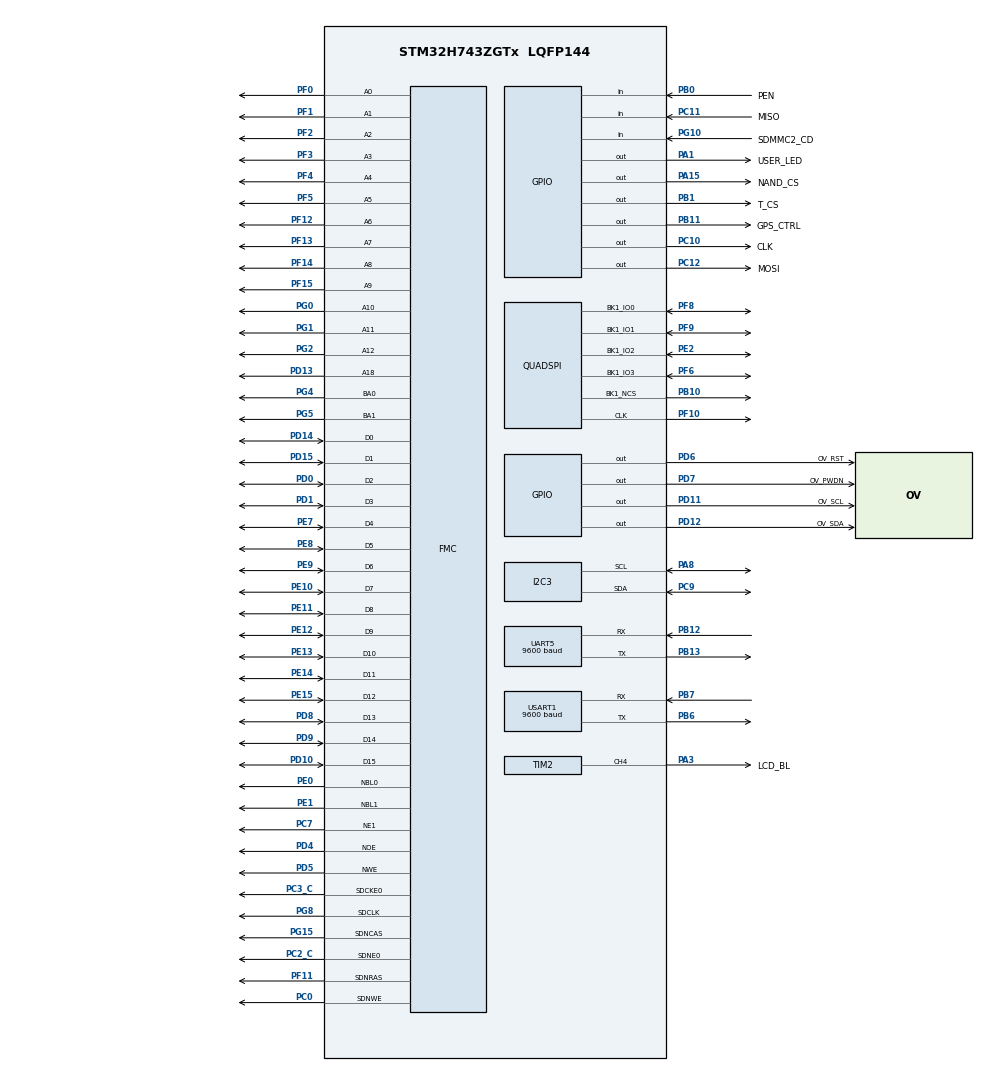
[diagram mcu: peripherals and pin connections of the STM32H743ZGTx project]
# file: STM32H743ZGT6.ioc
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CORTEX_M7.AccessPermission_S-Cortex_Memory_Protection_Unit_Region1_Settings_S=MPU_REGION_FULL_ACCESS
CORTEX_M7.AccessPermission_S-Cortex_Memory_Protection_Unit_Region2_Settings_S=MPU_REGION_FULL_ACCESS
CORTEX_M7.AccessPermission_Spec=MPU_REGION_FULL_ACCESS
CORTEX_M7.BaseAddress_S-Cortex_Memory_Protection_Unit_Region1_Settings_S=0xC0000000
CORTEX_M7.BaseAddress_S-Cortex_Memory_Protection_Unit_Region2_Settings_S=0x24000000
CORTEX_M7.BaseAddress_Spec=0x60000000
CORTEX_M7.CPU_DCache=Enabled
CORTEX_M7.CPU_ICache=Enabled
CORTEX_M7.DisableExec_Spec=MPU_INSTRUCTION_ACCESS_ENABLE
CORTEX_M7.Enable_S-Cortex_Memory_Protection_Unit_Region1_Settings_S=MPU_REGION_ENABLE
CORTEX_M7.Enable_S-Cortex_Memory_Protection_Unit_Region2_Settings_S=MPU_REGION_ENABLE
CORTEX_M7.IsBufferable_S-Cortex_Memory_Protection_Unit_Region1_Settings_S=MPU_ACCESS_BUFFERABLE
CORTEX_M7.IsBufferable_S-Cortex_Memory_Protection_Unit_Region2_Settings_S=MPU_ACCESS_BUFFERABLE
CORTEX_M7.IsBufferable_Spec=MPU_ACCESS_BUFFERABLE
CORTEX_M7.IsCacheable_S-Cortex_Memory_Protection_Unit_Region1_Settings_S=MPU_ACCESS_CACHEABLE
CORTEX_M7.IsCacheable_S-Cortex_Memory_Protection_Unit_Region2_Settings_S=MPU_ACCESS_CACHEABLE
CORTEX_M7.IsCacheable_Spec=MPU_ACCESS_NOT_CACHEABLE
CORTEX_M7.IsShareable_Spec=MPU_ACCESS_NOT_SHAREABLE
CORTEX_M7.Size_S-Cortex_Memory_Protection_Unit_Region1_Settings_S=MPU_REGION_SIZE_32MB
CORTEX_M7.Size_S-Cortex_Memory_Protection_Unit_Region2_Settings_S=MPU_REGION_SIZE_512KB
CORTEX_M7.Size_Spec=MPU_REGION_SIZE_256MB
CORTEX_M7.SubRegionDisable_Spec=0x0
CORTEX_M7.default_mode_Activation=1
Dma.MEMTOMEM.0.Direction=DMA_MEMORY_TO_MEMORY
Dma.MEMTOMEM.0.EventEnable=DISABLE
Dma.MEMTOMEM.0.FIFOMode=DMA_FIFOMODE_ENABLE
Dma.MEMTOMEM.0.FIFOThreshold=DMA_FIFO_THRESHOLD_FULL
Dma.MEMTOMEM.0.Instance=DMA2_Stream0
Dma.MEMTOMEM.0.MemBurst=DMA_MBURST_SINGLE
Dma.MEMTOMEM.0.MemDataAlignment=DMA_MDATAALIGN_HALFWORD
Dma.MEMTOMEM.0.MemInc=DMA_MINC_ENABLE
Dma.MEMTOMEM.0.Mode=DMA_NORMAL
Dma.MEMTOMEM.0.PeriphBurst=DMA_PBURST_SINGLE
Dma.MEMTOMEM.0.PeriphDataAlignment=DMA_PDATAALIGN_HALFWORD
Dma.MEMTOMEM.0.PeriphInc=DMA_PINC_ENABLE
Dma.MEMTOMEM.0.Polarity=HAL_DMAMUX_REQ_GEN_RISING
Dma.MEMTOMEM.0.Priority=DMA_PRIORITY_HIGH
Dma.MEMTOMEM.0.RequestNumber=1
Dma.MEMTOMEM.0.SignalID=NONE
Dma.MEMTOMEM.0.SyncEnable=DISABLE
Dma.MEMTOMEM.0.SyncPolarity=HAL_DMAMUX_SYNC_NO_EVENT
Dma.MEMTOMEM.0.SyncRequestNumber=1
Dma.MEMTOMEM.0.SyncSignalID=NONE
Dma.Request0=MEMTOMEM
FATFS._CODE_PAGE=936
FATFS._MAX_SS=4096
FATFS._USE_FIND=1
FATFS._USE_LFN=2
FMC.BusTurnAroundDuration1=0
FMC.CASLatency1=FMC_SDRAM_CAS_LATENCY_3
FMC.ColumnBitsNumber1=FMC_SDRAM_COLUMN_BITS_NUM_9
FMC.DataSetupTime1=60
FMC.ExitSelfRefreshDelay1=8
FMC.ExtendedAddressSetupTime1=9
FMC.ExtendedBusTurnAroundDuration1=0
FMC.ExtendedDataSetupTime1=8
FMC.ExtendedMode1=FMC_EXTENDED_MODE_ENABLE
FMC.LoadToActiveDelay1=2
FMC.RCDDelay1=4
FMC.RPDelay1=2
FMC.RPDelay2=2
FMC.ReadBurst1=FMC_SDRAM_RBURST_ENABLE
FMC.ReadBurst2=FMC_SDRAM_RBURST_ENABLE
FMC.RowCycleDelay1=6
FMC.RowCycleDelay2=6
FMC.SDClockPeriod1=FMC_SDRAM_CLOCK_PERIOD_2
FMC.SDClockPeriod2=FMC_SDRAM_CLOCK_PERIOD_2
FMC.SelfRefreshTime1=6
FMC.WriteFifo1=FMC_WRITE_FIFO_ENABLE
FMC.WriteRecoveryTime1=2
I2C3.Timing=0x307075B1
Mcu.Family=STM32H7
Mcu.Name=STM32H743ZGTx
Mcu.Package=LQFP144
Mdma.MDMA_Channel0.QUADSPI_FIFO_TH.0.BlockCount=0
Mdma.MDMA_Channel0.QUADSPI_FIFO_TH.0.BlockDataLength=0
Mdma.MDMA_Channel0.QUADSPI_FIFO_TH.0.BufferTransferLength=128
Mdma.MDMA_Channel0.QUADSPI_FIFO_TH.0.CircularMode=MDMA_LINEAR_LIST
Mdma.MDMA_Channel0.QUADSPI_FIFO_TH.0.DataAlignment=MDMA_DATAALIGN_PACKENABLE
Mdma.MDMA_Channel0.QUADSPI_FIFO_TH.0.DestBlockAddressOffset=0
Mdma.MDMA_Channel0.QUADSPI_FIFO_TH.0.DestBurst=MDMA_DEST_BURST_SINGLE
Mdma.MDMA_Channel0.QUADSPI_FIFO_TH.0.DestDataSize=MDMA_DEST_DATASIZE_BYTE
Mdma.MDMA_Channel0.QUADSPI_FIFO_TH.0.DestinationInc=MDMA_DEST_INC_DISABLE
Mdma.MDMA_Channel0.QUADSPI_FIFO_TH.0.DstAddress=0
Mdma.MDMA_Channel0.QUADSPI_FIFO_TH.0.Endianness=MDMA_LITTLE_ENDIANNESS_PRESERVE
Mdma.MDMA_Channel0.QUADSPI_FIFO_TH.0.Instance=MDMA_Channel0
Mdma.MDMA_Channel0.QUADSPI_FIFO_TH.0.MaskAddress=0
Mdma.MDMA_Channel0.QUADSPI_FIFO_TH.0.MaskData=0
Mdma.MDMA_Channel0.QUADSPI_FIFO_TH.0.Priority=MDMA_PRIORITY_MEDIUM
Mdma.MDMA_Channel0.QUADSPI_FIFO_TH.0.Rank=First
Mdma.MDMA_Channel0.QUADSPI_FIFO_TH.0.SourceBlockAddressOffset=0
Mdma.MDMA_Channel0.QUADSPI_FIFO_TH.0.SourceBurst=MDMA_SOURCE_BURST_SINGLE
Mdma.MDMA_Channel0.QUADSPI_FIFO_TH.0.SourceDataSize=MDMA_SRC_DATASIZE_BYTE
Mdma.MDMA_Channel0.QUADSPI_FIFO_TH.0.SourceInc=MDMA_SRC_INC_BYTE
Mdma.MDMA_Channel0.QUADSPI_FIFO_TH.0.SrcAddress=0
Mdma.MDMA_Channel0.QUADSPI_FIFO_TH.0.TransferTriggerMode=MDMA_BUFFER_TRANSFER
Mdma.MDMA_Channel0.Request0=QUADSPI_FIFO_TH
Mdma.MDMA_Channel0.RequestsNb=1
Mdma.RequestSet0=MDMA_Channel0
Mdma.RequestSetsNb=1
NVIC.DMA2_Stream0_IRQn=true\:0\:0\:false\:false\:true\:true\:true\:true
NVIC.MDMA_IRQn=true\:0\:0\:false\:false\:true\:false\:true\:true
NVIC.PriorityGroup=NVIC_PRIORITYGROUP_4
NVIC.QUADSPI_IRQn=true\:0\:0\:true\:false\:true\:true\:true\:true
NVIC.TIM3_IRQn=true\:1\:0\:true\:false\:true\:true\:true\:true
NVIC.UART5_IRQn=true\:2\:0\:true\:false\:true\:true\:true\:true
NVIC.USART1_IRQn=true\:2\:0\:true\:false\:true\:true\:true\:true
PA1.GPIO_Label=USER_LED
PA1.Signal=GPIO_Output
PA11.Signal=USB_OTG_FS_DM
PA12.Signal=USB_OTG_FS_DP
PA13\ (JTMS/SWDIO).Mode=Serial_Wire
PA13\ (JTMS/SWDIO).Signal=DEBUG_JTMS-SWDIO
PA14\ (JTCK/SWCLK).Mode=Serial_Wire
PA14\ (JTCK/SWCLK).Signal=DEBUG_JTCK-SWCLK
PA15\ (JTDI).GPIO_Label=NAND_CS
PA15\ (JTDI).Signal=GPIO_Output
PA3.GPIO_Label=LCD_BL
PA3.Signal=S_TIM2_CH4
PA8.Mode=I2C
PA8.Signal=I2C3_SCL
PB0.GPIO_Label=PEN
PB0.GPIO_PuPd=GPIO_PULLUP
PB0.Signal=GPIO_Input
PB1.GPIO_Label=T_CS
PB1.Signal=GPIO_Output
PB10.GPIO_PuPd=GPIO_NOPULL
PB10.GPIO_Speed=GPIO_SPEED_FREQ_VERY_HIGH
PB10.Mode=Single Bank 1
PB10.Signal=QUADSPI_BK1_NCS
PB11.GPIO_Label=GPS_CTRL
PB11.GPIO_PuPd=GPIO_PULLUP
PB11.GPIO_Speed=GPIO_SPEED_FREQ_MEDIUM
PB11.PinState=GPIO_PIN_RESET
PB11.Signal=GPIO_Output
PB12.Mode=Asynchronous
PB12.Signal=UART5_RX
PB13.Mode=Asynchronous
PB13.Signal=UART5_TX
PB6.Mode=Asynchronous
PB6.Signal=USART1_TX
PB7.Mode=Asynchronous
PB7.Signal=USART1_RX
PC0.Signal=FMC_SDNWE
PC10.GPIO_Label=CLK
PC10.Signal=GPIO_Output
PC11.GPIO_Label=MISO
PC11.GPIO_PuPd=GPIO_PULLUP
PC11.Signal=GPIO_Input
PC12.GPIO_Label=MOSI
PC12.Signal=GPIO_Output
PC14-OSC32_IN\ (OSC32_IN).Signal=RCC_OSC32_IN
PC15-OSC32_OUT\ (OSC32_OUT).Signal=RCC_OSC32_OUT
PC2_C.Mode=SdramChipSelect1_1
PC2_C.Signal=FMC_SDNE0
PC3_C.Mode=SdramChipSelect1_1
PC3_C.Signal=FMC_SDCKE0
PC7.Mode=NorPsramChipSelect1_1
PC7.Signal=FMC_NE1
PC9.Mode=I2C
PC9.Signal=I2C3_SDA
PD0.Signal=FMC_D2_DA2
PD1.Signal=FMC_D3_DA3
PD10.Signal=FMC_D15_DA15
PD11.GPIO_Label=OV_SCL
PD11.GPIO_Speed=GPIO_SPEED_FREQ_HIGH
PD11.Signal=GPIO_Output
PD12.GPIO_Label=OV_SDA
PD12.GPIO_Speed=GPIO_SPEED_FREQ_HIGH
PD12.Signal=GPIO_Output
PD13.Signal=FMC_A18
PD14.Signal=FMC_D0_DA0
PD15.Signal=FMC_D1_DA1
PD4.Signal=FMC_NOE
PD5.Signal=FMC_NWE
PD6.GPIO_Label=OV_RST
PD6.GPIO_PuPd=GPIO_PULLUP
PD6.Signal=GPIO_Output
PD7.GPIO_Label=OV_PWDN
PD7.GPIO_PuPd=GPIO_PULLUP
PD7.Signal=GPIO_Output
PD8.Signal=FMC_D13_DA13
PD9.Signal=FMC_D14_DA14
PE0.Signal=FMC_NBL0
PE1.Signal=FMC_NBL1
PE10.Signal=FMC_D7_DA7
PE11.Signal=FMC_D8_DA8
PE12.Signal=FMC_D9_DA9
PE13.Signal=FMC_D10_DA10
PE14.Signal=FMC_D11_DA11
PE15.Signal=FMC_D12_DA12
PE2.GPIO_Speed=GPIO_SPEED_FREQ_VERY_HIGH
PE2.Mode=Single Bank 1
PE2.Signal=QUADSPI_BK1_IO2
PE7.Signal=FMC_D4_DA4
PE8.Signal=FMC_D5_DA5
PE9.Signal=FMC_D6_DA6
PF0.Signal=FMC_A0
PF1.Signal=FMC_A1
PF10.GPIO_PuPd=GPIO_NOPULL
PF10.GPIO_Speed=GPIO_SPEED_FREQ_VERY_HIGH
PF10.Mode=Single Bank 1
PF10.Signal=QUADSPI_CLK
PF11.Signal=FMC_SDNRAS
PF12.Signal=FMC_A6
PF13.Signal=FMC_A7
PF14.Signal=FMC_A8
PF15.Signal=FMC_A9
PF2.Signal=FMC_A2
PF3.Signal=FMC_A3
PF4.Signal=FMC_A4
PF5.Signal=FMC_A5
PF6.GPIO_Speed=GPIO_SPEED_FREQ_VERY_HIGH
PF6.Mode=Single Bank 1
PF6.Signal=QUADSPI_BK1_IO3
PF8.GPIO_Speed=GPIO_SPEED_FREQ_VERY_HIGH
PF8.Mode=Single Bank 1
PF8.Signal=QUADSPI_BK1_IO0
PF9.GPIO_Speed=GPIO_SPEED_FREQ_VERY_HIGH
PF9.Mode=Single Bank 1
PF9.Signal=QUADSPI_BK1_IO1
PG0.Signal=FMC_A10
PG1.Signal=FMC_A11
PG10.GPIO_Label=SDMMC2_CD
PG10.Signal=GPIO_Input
PG15.Signal=FMC_SDNCAS
PG2.Signal=FMC_A12
PG4.Signal=FMC_A14_BA0
PG5.Signal=FMC_A15_BA1
PG8.Signal=FMC_SDCLK
PG9.Signal=DCMI_VSYNC
PH0-OSC_IN\ (PH0).Mode=HSE-External-Oscillator
PH0-OSC_IN\ (PH0).Signal=RCC_OSC_IN
PH1-OSC_OUT\ (PH1).Mode=HSE-External-Oscillator
PH1-OSC_OUT\ (PH1).Signal=RCC_OSC_OUT
ProjectManager.HeapSize=0x2000
ProjectManager.StackSize=0x4000
ProjectManager.TargetToolchain=MDK-ARM V5.32
QUADSPI.ClockMode=QSPI_CLOCK_MODE_3
QUADSPI.ClockPrescaler=2
QUADSPI.FifoThreshold=4
QUADSPI.FlashSize=25
QUADSPI.SampleShifting=QSPI_SAMPLE_SHIFTING_HALFCYCLE
RCC.ADCFreq_Value=50390625
RCC.APB1Freq_Value=120000000
RCC.APB2Freq_Value=120000000
RCC.APB3Freq_Value=120000000
RCC.APB4Freq_Value=120000000
RCC.CortexFreq_Value=480000000
RCC.D1PPRE=RCC_APB3_DIV2
RCC.D2PPRE1=RCC_APB1_DIV2
RCC.D2PPRE2=RCC_APB2_DIV2
RCC.D3PPRE=RCC_APB4_DIV2
RCC.DIVM1=5
RCC.DIVN1=192
RCC.DIVQ1=13
RCC.HCLKFreq_Value=240000000
RCC.HPRE=RCC_HCLK_DIV2
RCC.HSE_VALUE=25000000
RCC.PLL2FRACN=0
RCC.PLL3FRACN=0
RCC.PLLFRACN=0
RCC.PLLSourceVirtual=RCC_PLLSOURCE_HSE
RCC.SYSCLKFreq_VALUE=480000000
RCC.SYSCLKSource=RCC_SYSCLKSOURCE_PLLCLK
RCC.SupplySource=PWR_LDO_SUPPLY
RCC.Tim1Mul=1
RCC.USBFreq_Value=73846153.84615384
SH.FMC_A0.0=FMC_A0,13b-sda1
SH.FMC_A1.0=FMC_A1,13b-sda1
SH.FMC_A10.0=FMC_A10,13b-sda1
SH.FMC_A11.0=FMC_A11,13b-sda1
SH.FMC_A12.0=FMC_A12,13b-sda1
SH.FMC_A14_BA0.0=FMC_BA0,FourSdramBanks1
SH.FMC_A15_BA1.0=FMC_BA1,FourSdramBanks1
SH.FMC_A18.0=FMC_A18,A18_1
SH.FMC_A2.0=FMC_A2,13b-sda1
SH.FMC_A3.0=FMC_A3,13b-sda1
SH.FMC_A4.0=FMC_A4,13b-sda1
SH.FMC_A5.0=FMC_A5,13b-sda1
SH.FMC_A6.0=FMC_A6,13b-sda1
SH.FMC_A7.0=FMC_A7,13b-sda1
SH.FMC_A8.0=FMC_A8,13b-sda1
SH.FMC_A9.0=FMC_A9,13b-sda1
SH.FMC_D0_DA0.0=FMC_D0,16b-d1
SH.FMC_D0_DA0.1=FMC_D0,sd-16b-d1
SH.FMC_D10_DA10.0=FMC_D10,16b-d1
SH.FMC_D10_DA10.1=FMC_D10,sd-16b-d1
SH.FMC_D11_DA11.0=FMC_D11,16b-d1
SH.FMC_D11_DA11.1=FMC_D11,sd-16b-d1
SH.FMC_D12_DA12.0=FMC_D12,16b-d1
SH.FMC_D12_DA12.1=FMC_D12,sd-16b-d1
SH.FMC_D13_DA13.0=FMC_D13,16b-d1
SH.FMC_D13_DA13.1=FMC_D13,sd-16b-d1
SH.FMC_D14_DA14.0=FMC_D14,16b-d1
SH.FMC_D14_DA14.1=FMC_D14,sd-16b-d1
SH.FMC_D15_DA15.0=FMC_D15,16b-d1
SH.FMC_D15_DA15.1=FMC_D15,sd-16b-d1
SH.FMC_D1_DA1.0=FMC_D1,16b-d1
SH.FMC_D1_DA1.1=FMC_D1,sd-16b-d1
SH.FMC_D2_DA2.0=FMC_D2,16b-d1
SH.FMC_D2_DA2.1=FMC_D2,sd-16b-d1
SH.FMC_D3_DA3.0=FMC_D3,16b-d1
SH.FMC_D3_DA3.1=FMC_D3,sd-16b-d1
SH.FMC_D4_DA4.0=FMC_D4,16b-d1
SH.FMC_D4_DA4.1=FMC_D4,sd-16b-d1
SH.FMC_D5_DA5.0=FMC_D5,16b-d1
SH.FMC_D5_DA5.1=FMC_D5,sd-16b-d1
SH.FMC_D6_DA6.0=FMC_D6,16b-d1
SH.FMC_D6_DA6.1=FMC_D6,sd-16b-d1
SH.FMC_D7_DA7.0=FMC_D7,16b-d1
SH.FMC_D7_DA7.1=FMC_D7,sd-16b-d1
SH.FMC_D8_DA8.0=FMC_D8,16b-d1
SH.FMC_D8_DA8.1=FMC_D8,sd-16b-d1
SH.FMC_D9_DA9.0=FMC_D9,16b-d1
SH.FMC_D9_DA9.1=FMC_D9,sd-16b-d1
SH.FMC_NBL0.0=FMC_NBL0,Sd2ByteEnable1
SH.FMC_NBL1.0=FMC_NBL1,Sd2ByteEnable1
SH.FMC_NOE.0=FMC_NOE,Lcd1
SH.FMC_NWE.0=FMC_NWE,Lcd1
SH.FMC_SDCLK.0=FMC_SDCLK,13b-sda1
SH.FMC_SDNCAS.0=FMC_SDNCAS,13b-sda1
SH.FMC_SDNRAS.0=FMC_SDNRAS,13b-sda1
SH.FMC_SDNWE.0=FMC_SDNWE,13b-sda1
SH.S_TIM2_CH4.0=TIM2_CH4,PWM Generation4 CH4
TIM2.AutoReloadPreload=TIM_AUTORELOAD_PRELOAD_ENABLE
TIM2.Channel-PWM\ Generation4\ CH4=TIM_CHANNEL_4
TIM2.Period=1001
TIM2.Prescaler=119
TIM3.AutoReloadPreload=TIM_AUTORELOAD_PRELOAD_ENABLE
TIM3.Period=9999
TIM3.Prescaler=11999
UART5.BaudRate=9600
USART1.BaudRate=9600
USART1.VirtualMode-Asynchronous=VM_ASYNC
VP_FATFS_VS_Generic.Mode=User_defined
VP_MEMORYMAP_VS_MEMORYMAP.Mode=CurAppReg
VP_TIM3_VS_ClockSourceINT.Mode=Internal
board=custom

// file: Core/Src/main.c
/* USER CODE BEGIN Header */
/**
 ******************************************************************************
 * @file           : main.c
 * @brief          : Main program body
 ******************************************************************************
 * @attention
 *
 * Copyright (c) 2024 STMicroelectronics.
 * All rights reserved.
 *
 * This software is licensed under terms that can be found in the LICENSE file
 * in the root directory of this software component.
 * If no LICENSE file comes with this software, it is provided AS-IS.
 *
 ******************************************************************************
 */
/* USER CODE END Header */
#include "main.h"
#include "dma.h"
#include "fatfs.h"
#include "i2c.h"
#include "mdma.h"
#include "memorymap.h"
#include "quadspi.h"
#include "tim.h"
#include "usart.h"
#include "gpio.h"
#include "fmc.h"

/* USER CODE BEGIN Includes */
#include <stdio.h>
/* USER CODE END Includes */

/* USER CODE BEGIN PV */
lv_ui guider_ui;
GPS_Data gps;
/* USER CODE END PV */

void SystemClock_Config(void);
static void MPU_Config(void);

/* USER CODE BEGIN 0 */
void delay_us(uint32_t udelay)
{
  uint32_t startval, tickn, delays, wait;

  startval = SysTick->VAL;
  tickn = HAL_GetTick();
  delays = udelay * 480; // sysc / 1000 * udelay;
  if (delays > startval)
  {
    while (HAL_GetTick() == tickn)
    {
    }
    wait = 480000 + startval - delays;
    while (wait < SysTick->VAL)
    {
    }
  }
  else
  {
    wait = startval - delays;
    while (wait < SysTick->VAL && HAL_GetTick() == tickn)
    {
    }
  }
}

// printf重定向
#pragma import(__use_no_semihosting)
// 标准库需要的支持函数
struct __FILE
{
  int handle;
};

FILE __stdout;
// 定义_sys_exit()以避免使用半主机模式
void _sys_exit(int x)
{
  x = x;
}
void _ttywrch(int ch)
{
  ch = ch;
}

// 重定义fputc函数
int fputc(int ch, FILE *f)
{
  HAL_UART_Transmit(&huart1, (uint8_t *)&ch, 1, 0x200); // 根据使用的库重定向
  return ch;
}

// LVGL FS test
lv_fs_file_t lv_file;
void lvgl_fs_test()
{

  lv_fs_res_t lv_res;
  uint8_t ReadBuffer[1024] = {0};
  uint32_t fnum;
  lv_res = lv_fs_open(&lv_file, "0:test111.txt", LV_FS_MODE_RD);
  if (lv_res != LV_FS_RES_OK)
  {
    printf("LVGL FS open error. (%d)\n", lv_res);
  }
  else
  {
    printf("LVGL FS open Ok\n");
    lv_res = lv_fs_read(&lv_file, ReadBuffer, sizeof(ReadBuffer), &fnum);
    if (lv_res != LV_FS_RES_OK)
    {
      printf("LVGL FS read error. (%d)\n", lv_res);
      return;
    }
    else{
      printf("LVGL FS read Ok\n");
		printf("%s\n",ReadBuffer);
	}
    lv_fs_close(&lv_file);
  }

//  lv_res = lv_fs_open(&lv_file, "0:serial.bmp", LV_FS_MODE_WR);
//  if (lv_res != LV_FS_RES_OK)
//  {
//    printf("LVGL FS open error. (%d)\n", lv_res);
//  }
//  else
//  {
//    printf("LVGL FS open Ok\n");
//	  uint8_t tempc[] = "hello,test";
//	  uint32_t wb;
//	  lv_res = lv_fs_write(&lv_file,tempc,sizeof(tempc),&wb);
//	  printf("wb=%d",wb);
//    //lv_res = lv_fs_write(&lv_file,_serial_alpha_80x80.data,_serial_alpha_80x80.data_size,NULL);
//    if (lv_res != LV_FS_RES_OK)
//    {
//      printf("LVGL FS write error. (%d)\n", lv_res);
//      return;
//    }
//    else{
//      printf("LVGL FS write Ok\n");
//	}
//    lv_fs_close(&lv_file);
//  }
//  // 读取总空间及剩余空间
//    DWORD fre_clust;
//    FATFS *fs_temp;
//    f_getfree("0:", &fre_clust, &fs_temp);
//    DWORD tot_sect = (fs_temp->n_fatent - 2) * fs_temp->csize;
//    DWORD fre_sect = fre_clust * fs_temp->csize;
//#if _MAX_SS != 512 // 扇区大小不是512字节,则转换为512字节
//    tot_sect *= fs_temp->ssize / 512;
//    fre_sect *= fs_temp->ssize / 512;
//#endif
//    printf("%10lu KB total drive space.\n%10lu KB available.\n", tot_sect >> 1, fre_sect >> 1);
//    // 当前目录下的文件
//    char buff[256];
//    strcpy(buff, "0:/");
//    scan_files(buff);
}

/* USER CODE END 0 */

int main(void)
{

  /* MPU Configuration--------------------------------------------------------*/
  MPU_Config();

  /* Enable the CPU Cache */

  /* Enable I-Cache---------------------------------------------------------*/
  SCB_EnableICache();

  /* Enable D-Cache---------------------------------------------------------*/
  SCB_EnableDCache();

  /* MCU Configuration--------------------------------------------------------*/

  /* Reset of all peripherals, Initializes the Flash interface and the Systick. */
  HAL_Init();

  /* Configure the system clock */
  SystemClock_Config();

  /* Initialize all configured peripherals */
  MX_GPIO_Init();
  MX_DMA_Init();
  MX_MDMA_Init();
  MX_FMC_Init();
  MX_I2C3_Init();
  MX_QUADSPI_Init();
  MX_UART5_Init();
  MX_USART1_UART_Init();
  MX_TIM2_Init();
  MX_TIM3_Init();
  MX_FATFS_Init();
  /* USER CODE BEGIN 2 */
  // 使能TIM3定时器中断
  HAL_TIM_Base_Start_IT(&htim3);
  // 注册DMA回调函数
  HAL_DMA_RegisterCallback(&hdma_memtomem_dma2_stream0, HAL_DMA_XFER_CPLT_CB_ID, LVGL_LCD_FSMC_DMA_pCallback);
  // 初始化LCD屏幕
  LCD_Init();
  // 设置PWM调光
  HAL_TIM_PWM_Start(&htim2, TIM_CHANNEL_4);
  read_settings();
  __HAL_TIM_SetCompare(&htim2, TIM_CHANNEL_4, 500);
  // 初始化LVGL
  lv_init();
  lv_port_disp_init();
  lv_port_indev_init();
  lv_port_fs_init();
  // 初始化UI及事件
  setup_ui(&guider_ui);
  events_init(&guider_ui);
  // 给BH1750发送命令，连续获取光照
  uint8_t opeCode = BH1750_CONT_HI_RSLT_1;
  BH1750_WriteOpecode(&opeCode, 1);
  // 默认关闭GPS
  HAL_GPIO_WritePin(GPS_CTRL_GPIO_Port, GPS_CTRL_Pin, GPIO_PIN_RESET);
  // 首次烧录若未校准触摸屏幕，则先校准
  if (!TP_Get_Adjdata())
  {
    tp_dev.adjust();
  }
  // 测试外部flash读写速度
  //  sfWriteTest();
  //  sfTestReadSpeed();
  // 初始化QSPI Flash
  BSP_QSPI_Init();
  // 文件系统测试
  //  FATFS_FLASH_Test();
  //  scan_files("0:");

 // lvgl_fs_test();

  /* USER CODE END 2 */

  /* Infinite loop */
  while (1)
  {

    /* USER CODE BEGIN 3 */

    // 扫描屏幕是否按下
    tp_dev.scan(0);
    lv_task_handler();
  }
  /* USER CODE END 3 */
}

void SystemClock_Config(void)
{
  RCC_OscInitTypeDef RCC_OscInitStruct = {0};
  RCC_ClkInitTypeDef RCC_ClkInitStruct = {0};

  /** Supply configuration update enable
   */
  HAL_PWREx_ConfigSupply(PWR_LDO_SUPPLY);

  /** Configure the main internal regulator output voltage
   */
  __HAL_PWR_VOLTAGESCALING_CONFIG(PWR_REGULATOR_VOLTAGE_SCALE1);

  while (!__HAL_PWR_GET_FLAG(PWR_FLAG_VOSRDY))
  {
  }

  __HAL_RCC_SYSCFG_CLK_ENABLE();
  __HAL_PWR_VOLTAGESCALING_CONFIG(PWR_REGULATOR_VOLTAGE_SCALE0);

  while (!__HAL_PWR_GET_FLAG(PWR_FLAG_VOSRDY))
  {
  }

  /** Initializes the RCC Oscillators according to the specified parameters
   * in the RCC_OscInitTypeDef structure.
   */
  RCC_OscInitStruct.OscillatorType = RCC_OSCILLATORTYPE_HSE;
  RCC_OscInitStruct.HSEState = RCC_HSE_ON;
  RCC_OscInitStruct.PLL.PLLState = RCC_PLL_ON;
  RCC_OscInitStruct.PLL.PLLSource = RCC_PLLSOURCE_HSE;
  RCC_OscInitStruct.PLL.PLLM = 5;
  RCC_OscInitStruct.PLL.PLLN = 192;
  RCC_OscInitStruct.PLL.PLLP = 2;
  RCC_OscInitStruct.PLL.PLLQ = 13;
  RCC_OscInitStruct.PLL.PLLR = 2;
  RCC_OscInitStruct.PLL.PLLRGE = RCC_PLL1VCIRANGE_2;
  RCC_OscInitStruct.PLL.PLLVCOSEL = RCC_PLL1VCOWIDE;
  RCC_OscInitStruct.PLL.PLLFRACN = 0;
  if (HAL_RCC_OscConfig(&RCC_OscInitStruct) != HAL_OK)
  {
    Error_Handler();
  }

  /** Initializes the CPU, AHB and APB buses clocks
   */
  RCC_ClkInitStruct.ClockType = RCC_CLOCKTYPE_HCLK | RCC_CLOCKTYPE_SYSCLK | RCC_CLOCKTYPE_PCLK1 | RCC_CLOCKTYPE_PCLK2 | RCC_CLOCKTYPE_D3PCLK1 | RCC_CLOCKTYPE_D1PCLK1;
  RCC_ClkInitStruct.SYSCLKSource = RCC_SYSCLKSOURCE_PLLCLK;
  RCC_ClkInitStruct.SYSCLKDivider = RCC_SYSCLK_DIV1;
  RCC_ClkInitStruct.AHBCLKDivider = RCC_HCLK_DIV2;
  RCC_ClkInitStruct.APB3CLKDivider = RCC_APB3_DIV2;
  RCC_ClkInitStruct.APB1CLKDivider = RCC_APB1_DIV2;
  RCC_ClkInitStruct.APB2CLKDivider = RCC_APB2_DIV2;
  RCC_ClkInitStruct.APB4CLKDivider = RCC_APB4_DIV2;

  if (HAL_RCC_ClockConfig(&RCC_ClkInitStruct, FLASH_LATENCY_4) != HAL_OK)
  {
    Error_Handler();
  }
}

/* MPU Configuration */

void MPU_Config(void)
{
  MPU_Region_InitTypeDef MPU_InitStruct = {0};

  /* Disables the MPU */
  HAL_MPU_Disable();

  /** Initializes and configures the Region and the memory to be protected
   */
  MPU_InitStruct.Enable = MPU_REGION_ENABLE;
  MPU_InitStruct.Number = MPU_REGION_NUMBER0;
  MPU_InitStruct.BaseAddress = 0x60000000;
  MPU_InitStruct.Size = MPU_REGION_SIZE_256MB;
  MPU_InitStruct.SubRegionDisable = 0x0;
  MPU_InitStruct.TypeExtField = MPU_TEX_LEVEL0;
  MPU_InitStruct.AccessPermission = MPU_REGION_FULL_ACCESS;
  MPU_InitStruct.DisableExec = MPU_INSTRUCTION_ACCESS_ENABLE;
  MPU_InitStruct.IsShareable = MPU_ACCESS_NOT_SHAREABLE;
  MPU_InitStruct.IsCacheable = MPU_ACCESS_NOT_CACHEABLE;
  MPU_InitStruct.IsBufferable = MPU_ACCESS_BUFFERABLE;

  HAL_MPU_ConfigRegion(&MPU_InitStruct);

  /** Initializes and configures the Region and the memory to be protected
   */
  MPU_InitStruct.Number = MPU_REGION_NUMBER1;
  MPU_InitStruct.BaseAddress = 0xC0000000;
  MPU_InitStruct.Size = MPU_REGION_SIZE_32MB;
  MPU_InitStruct.IsCacheable = MPU_ACCESS_CACHEABLE;

  HAL_MPU_ConfigRegion(&MPU_InitStruct);

  /** Initializes and configures the Region and the memory to be protected
   */
  MPU_InitStruct.Number = MPU_REGION_NUMBER2;
  MPU_InitStruct.BaseAddress = 0x24000000;
  MPU_InitStruct.Size = MPU_REGION_SIZE_512KB;

  HAL_MPU_ConfigRegion(&MPU_InitStruct);
  /* Enables the MPU */
  HAL_MPU_Enable(MPU_PRIVILEGED_DEFAULT);
}

void Error_Handler(void)
{
  __disable_irq();
  while (1)
  {
  }
}
